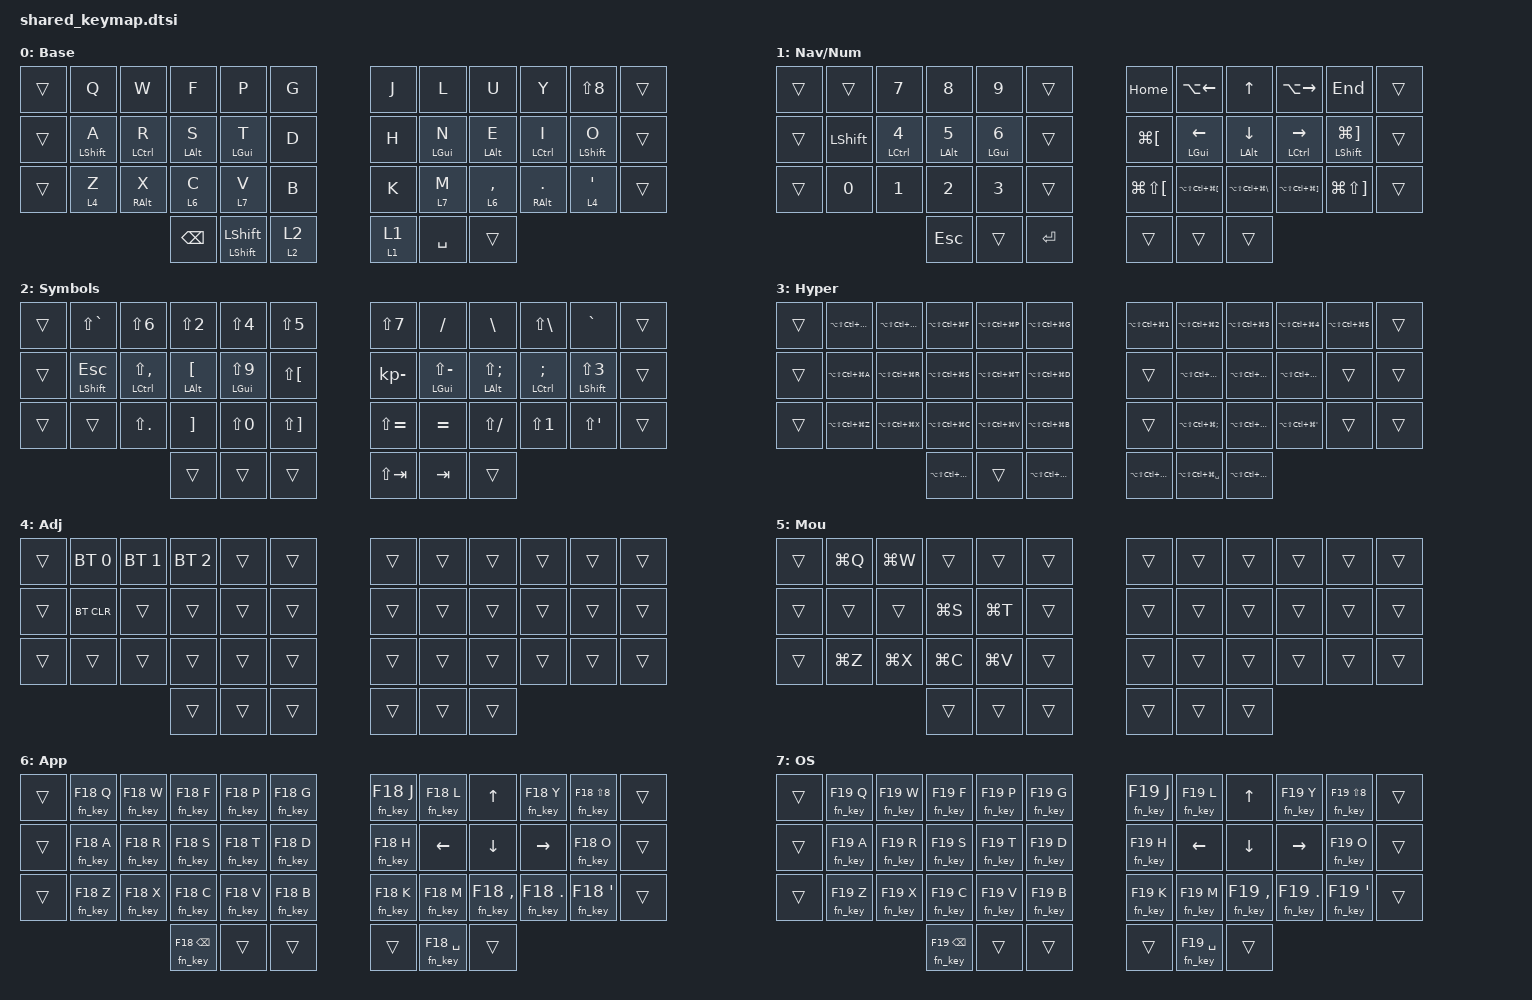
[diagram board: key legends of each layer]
// This file is automatically generated from keymap.txt
#include <behaviors.dtsi>
#include <dt-bindings/zmk/keys.h>
#include <dt-bindings/zmk/bt.h>

/ {
    // The hold-tap behaviors the keymap may use:
    // - mt_  holds a modifier, taps a key
    // - lt_  holds a layer, taps a key
    // - omt_ holds a modifier, one-shots it on tap
    // - olt_ holds a layer, one-shots it on tap
    // mt_ and lt_ come in the flavors the keymap can pick between: tp
    // (tap-preferred, the default, used on the home-row) and hp
    // (hold-preferred, used on the thumb keys). One-shot keys are always
    // tap-preferred, so that a quick tap always one-shots.
    //
    // hold-preferred takes the hold as soon as any other key goes down, which
    // is what makes a thumb layer engage without waiting, and also what made it
    // engage mid-word on a thumb key pressed inside a burst of typing. The hp
    // pair therefore refuses to hold at all within require-prior-idle-ms of the
    // last key press, so a thumb key only shifts a layer once typing has
    // actually paused, and quick-tap-ms keeps a repeated tap a tap.
    behaviors {
        mt_tp: mod_tap_tap_preferred {
            compatible = "zmk,behavior-hold-tap";
            #binding-cells = <2>;
            flavor = "tap-preferred";
            tapping-term-ms = <200>;
            bindings = <&kp>, <&kp>;
        };
        mt_hp: mod_tap_hold_preferred {
            compatible = "zmk,behavior-hold-tap";
            #binding-cells = <2>;
            flavor = "hold-preferred";
            tapping-term-ms = <200>;
            quick-tap-ms = <200>;
            require-prior-idle-ms = <150>;
            bindings = <&kp>, <&kp>;
        };

        lt_tp: layer_tap_tap_preferred {
            compatible = "zmk,behavior-hold-tap";
            #binding-cells = <2>;
            flavor = "tap-preferred";
            tapping-term-ms = <200>;
            bindings = <&mo>, <&kp>;
        };
        lt_hp: layer_tap_hold_preferred {
            compatible = "zmk,behavior-hold-tap";
            #binding-cells = <2>;
            flavor = "hold-preferred";
            tapping-term-ms = <200>;
            quick-tap-ms = <200>;
            require-prior-idle-ms = <150>;
            bindings = <&mo>, <&kp>;
        };

        omt_: oneshot_mod_tap {
            compatible = "zmk,behavior-hold-tap";
            #binding-cells = <2>;
            flavor = "tap-preferred";
            tapping-term-ms = <200>;
            bindings = <&kp>, <&sk>;
        };
        olt_: oneshot_layer_tap {
            compatible = "zmk,behavior-hold-tap";
            #binding-cells = <2>;
            flavor = "tap-preferred";
            tapping-term-ms = <200>;
            bindings = <&mo>, <&sl>;
        };
    };

    // App and OS layer keys send F18 or F19 together with another key. Neither
    // function key is a modifier, so this holds both until the key is released
    // and then lets the key up before the function key. A second chord of the
    // same function key started before the first is released can drop it early;
    // the layers are used one key at a time.
    macros {
        fn_key: fn_key {
            compatible = "zmk,behavior-macro-two-param";
            #binding-cells = <2>;
            wait-ms = <15>;
            tap-ms = <0>;
            bindings
                = <&macro_param_1to1>
                , <&macro_press &kp MACRO_PLACEHOLDER>
                , <&macro_param_2to1>
                , <&macro_press &kp MACRO_PLACEHOLDER>
                , <&macro_pause_for_release>
                , <&macro_param_2to1>
                , <&macro_release &kp MACRO_PLACEHOLDER>
                , <&macro_param_1to1>
                , <&macro_release &kp MACRO_PLACEHOLDER>
                ;
        };
    };

    keymap {
            compatible = "zmk,keymap";

            default_layer {
                    display-name = "Base";
                    bindings = <
&trans &kp Q &kp W &kp F &kp P &kp G &kp J &kp L &kp U &kp Y &kp LS(N8) &trans
&trans &mt_tp LSHFT A &mt_tp LCTRL R &mt_tp LALT S &mt_tp LGUI T &kp D &kp H &mt_tp LGUI N &mt_tp LALT E &mt_tp LCTRL I &mt_tp LSHFT O &trans
&trans &lt_tp 4 Z &mt_tp RALT X &lt_tp 6 C &lt_tp 7 V &kp B &kp K &lt_tp 7 M &lt_tp 6 COMMA &mt_tp RALT DOT &lt_tp 4 SQT &trans
&kp BKSP &omt_ LSHFT LSHFT &olt_ 2 2 &olt_ 1 1 &kp SPC &trans
                    >;
            };

            raise_layer {
                    display-name = "Nav/Num";
                    bindings = <
&trans &trans &kp N7 &kp N8 &kp N9 &trans &kp HOME &kp LA(LEFT) &kp UP &kp LA(RIGHT) &kp END &trans
&trans &kp LSHFT &mt_tp LCTRL N4 &mt_tp LALT N5 &mt_tp LGUI N6 &trans &kp LG(LBKT) &mt_tp LGUI LEFT &mt_tp LALT DOWN &mt_tp LCTRL RIGHT &mt_tp LSHFT LG(RBKT) &trans
&trans &kp N0 &kp N1 &kp N2 &kp N3 &trans &kp LG(LS(LBKT)) &kp LA(LS(LC(LG(LBKT)))) &kp LA(LS(LC(LG(BSLH)))) &kp LA(LS(LC(LG(RBKT)))) &kp LG(LS(RBKT)) &trans
&kp ESC &trans &kp RET &trans &trans &trans
                    >;
            };

            lower_layer {
                    display-name = "Symbols";
                    bindings = <
&trans &kp LS(GRAVE) &kp LS(N6) &kp LS(N2) &kp LS(N4) &kp LS(N5) &kp LS(N7) &kp FSLH &kp BSLH &kp LS(BSLH) &kp GRAVE &trans
&trans &mt_tp LSHFT ESC &mt_tp LCTRL LS(COMMA) &mt_tp LALT LBKT &mt_tp LGUI LS(N9) &kp LS(LBKT) &kp KP_MINUS &mt_tp LGUI LS(MINUS) &mt_tp LALT LS(SEMI) &mt_tp LCTRL SEMI &mt_tp LSHFT LS(N3) &trans
&trans &trans &kp LS(DOT) &kp RBKT &kp LS(N0) &kp LS(RBKT) &kp LS(EQUAL) &kp EQUAL &kp LS(FSLH) &kp LS(N1) &kp LS(SQT) &trans
&trans &trans &trans &kp LS(TAB) &kp TAB &trans
                    >;
            };

            hyper_layer {
                    display-name = "Hyper";
                    bindings = <
&trans &kp LA(LS(LC(LG(Q)))) &kp LA(LS(LC(LG(W)))) &kp LA(LS(LC(LG(F)))) &kp LA(LS(LC(LG(P)))) &kp LA(LS(LC(LG(G)))) &kp LA(LS(LC(LG(N1)))) &kp LA(LS(LC(LG(N2)))) &kp LA(LS(LC(LG(N3)))) &kp LA(LS(LC(LG(N4)))) &kp LA(LS(LC(LG(N5)))) &trans
&trans &kp LA(LS(LC(LG(A)))) &kp LA(LS(LC(LG(R)))) &kp LA(LS(LC(LG(S)))) &kp LA(LS(LC(LG(T)))) &kp LA(LS(LC(LG(D)))) &trans &kp LA(LS(LC(LG(LEFT)))) &kp LA(LS(LC(LG(UP)))) &kp LA(LS(LC(LG(RIGHT)))) &trans &trans
&trans &kp LA(LS(LC(LG(Z)))) &kp LA(LS(LC(LG(X)))) &kp LA(LS(LC(LG(C)))) &kp LA(LS(LC(LG(V)))) &kp LA(LS(LC(LG(B)))) &trans &kp LA(LS(LC(LG(SEMI)))) &kp LA(LS(LC(LG(DOWN)))) &kp LA(LS(LC(LG(SQT)))) &trans &trans
&kp LA(LS(LC(LG(ESC)))) &trans &kp LA(LS(LC(LG(TAB)))) &kp LA(LS(LC(LG(RET)))) &kp LA(LS(LC(LG(SPC)))) &kp LA(LS(LC(LG(BKSP))))
                    >;
            };

            adjust_layer {
                    display-name = "Adj";
                    bindings = <
&trans &bt BT_SEL 0 &bt BT_SEL 1 &bt BT_SEL 2 &trans &trans &trans &trans &trans &trans &trans &trans
&trans &bt BT_CLR &trans &trans &trans &trans &trans &trans &trans &trans &trans &trans
&trans &trans &trans &trans &trans &trans &trans &trans &trans &trans &trans &trans
&trans &trans &trans &trans &trans &trans
                    >;
            };

            mouse_layer {
                    display-name = "Mou";
                    bindings = <
&trans &kp LG(Q) &kp LG(W) &trans &trans &trans &trans &trans &trans &trans &trans &trans
&trans &trans &trans &kp LG(S) &kp LG(T) &trans &trans &trans &trans &trans &trans &trans
&trans &kp LG(Z) &kp LG(X) &kp LG(C) &kp LG(V) &trans &trans &trans &trans &trans &trans &trans
&trans &trans &trans &trans &trans &trans
                    >;
            };

            app_layer {
                    display-name = "App";
                    bindings = <
&trans &fn_key F18 Q &fn_key F18 W &fn_key F18 F &fn_key F18 P &fn_key F18 G &fn_key F18 J &fn_key F18 L &kp UP &fn_key F18 Y &fn_key F18 LS(N8) &trans
&trans &fn_key F18 A &fn_key F18 R &fn_key F18 S &fn_key F18 T &fn_key F18 D &fn_key F18 H &kp LEFT &kp DOWN &kp RIGHT &fn_key F18 O &trans
&trans &fn_key F18 Z &fn_key F18 X &fn_key F18 C &fn_key F18 V &fn_key F18 B &fn_key F18 K &fn_key F18 M &fn_key F18 COMMA &fn_key F18 DOT &fn_key F18 SQT &trans
&fn_key F18 BKSP &trans &trans &trans &fn_key F18 SPC &trans
                    >;
            };

            os_layer {
                    display-name = "OS";
                    bindings = <
&trans &fn_key F19 Q &fn_key F19 W &fn_key F19 F &fn_key F19 P &fn_key F19 G &fn_key F19 J &fn_key F19 L &kp UP &fn_key F19 Y &fn_key F19 LS(N8) &trans
&trans &fn_key F19 A &fn_key F19 R &fn_key F19 S &fn_key F19 T &fn_key F19 D &fn_key F19 H &kp LEFT &kp DOWN &kp RIGHT &fn_key F19 O &trans
&trans &fn_key F19 Z &fn_key F19 X &fn_key F19 C &fn_key F19 V &fn_key F19 B &fn_key F19 K &fn_key F19 M &fn_key F19 COMMA &fn_key F19 DOT &fn_key F19 SQT &trans
&fn_key F19 BKSP &trans &trans &trans &fn_key F19 SPC &trans
                    >;
            };
        };
    combos {
        compatible = "zmk,combos";
        combo_0 {
            timeout-ms = <50>;
            key-positions = <2 3>;
            bindings = <&kp ESC>;
            layers = <0>;
        };
        combo_1 {
            timeout-ms = <50>;
            key-positions = <8 9>;
            bindings = <&kp RET>;
            layers = <0>;
        };
    };
};

